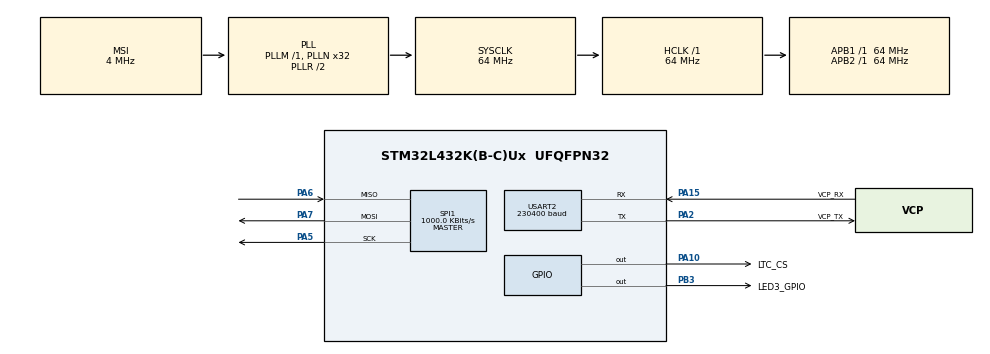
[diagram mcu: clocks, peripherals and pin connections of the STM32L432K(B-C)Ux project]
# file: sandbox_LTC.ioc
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Dma.Request0=USART2_RX
Dma.Request1=USART2_TX
Dma.USART2_RX.0.Direction=DMA_PERIPH_TO_MEMORY
Dma.USART2_RX.0.Instance=DMA1_Channel6
Dma.USART2_RX.0.MemDataAlignment=DMA_MDATAALIGN_BYTE
Dma.USART2_RX.0.MemInc=DMA_MINC_ENABLE
Dma.USART2_RX.0.Mode=DMA_CIRCULAR
Dma.USART2_RX.0.PeriphDataAlignment=DMA_PDATAALIGN_BYTE
Dma.USART2_RX.0.PeriphInc=DMA_PINC_DISABLE
Dma.USART2_RX.0.Priority=DMA_PRIORITY_VERY_HIGH
Dma.USART2_TX.1.Direction=DMA_MEMORY_TO_PERIPH
Dma.USART2_TX.1.Instance=DMA1_Channel7
Dma.USART2_TX.1.MemDataAlignment=DMA_MDATAALIGN_BYTE
Dma.USART2_TX.1.MemInc=DMA_MINC_ENABLE
Dma.USART2_TX.1.Mode=DMA_NORMAL
Dma.USART2_TX.1.PeriphDataAlignment=DMA_PDATAALIGN_BYTE
Dma.USART2_TX.1.PeriphInc=DMA_PINC_DISABLE
Dma.USART2_TX.1.Priority=DMA_PRIORITY_HIGH
Mcu.Family=STM32L4
Mcu.Name=STM32L432K(B-C)Ux
Mcu.Package=UFQFPN32
NVIC.DMA1_Channel6_IRQn=true\:0\:0\:false\:false\:true
NVIC.DMA1_Channel7_IRQn=true\:0\:0\:false\:false\:true
NVIC.PriorityGroup=NVIC_PRIORITYGROUP_4
NVIC.TIM6_DAC_IRQn=true\:0\:0\:false\:false\:true
NVIC.TimeBase=TIM6_DAC_IRQn
NVIC.TimeBaseIP=TIM6
NVIC.USART2_IRQn=true\:0\:0\:false\:false\:true
PA10.GPIO_Label=LTC_CS
PA10.Signal=GPIO_Output
PA13\ (JTMS-SWDIO).Mode=Serial_Wire
PA13\ (JTMS-SWDIO).Signal=SYS_JTMS-SWDIO
PA14\ (JTCK-SWCLK).Mode=Serial_Wire
PA14\ (JTCK-SWCLK).Signal=SYS_JTCK-SWCLK
PA15\ (JTDI).GPIO_Label=VCP_RX
PA15\ (JTDI).Mode=Asynchronous
PA15\ (JTDI).Signal=USART2_RX
PA2.GPIO_Label=VCP_TX
PA2.Mode=Asynchronous
PA2.Signal=USART2_TX
PA5.Mode=Full_Duplex_Master
PA5.Signal=SPI1_SCK
PA6.Mode=Full_Duplex_Master
PA6.Signal=SPI1_MISO
PA7.Mode=Full_Duplex_Master
PA7.Signal=SPI1_MOSI
PB3\ (JTDO-TRACESWO).GPIO_Label=LED3_GPIO
PB3\ (JTDO-TRACESWO).Signal=GPIO_Output
ProjectManager.HeapSize=0x200
ProjectManager.StackSize=0x400
ProjectManager.TargetToolchain=SW4STM32
RCC.AHBFreq_Value=64000000
RCC.APB1Freq_Value=64000000
RCC.APB1TimFreq_Value=64000000
RCC.APB2Freq_Value=64000000
RCC.APB2TimFreq_Value=64000000
RCC.CortexFreq_Value=64000000
RCC.HCLKFreq_Value=64000000
RCC.HSE_VALUE=8000000
RCC.HSI16_VALUE=16000000
RCC.HSI48_VALUE=48000000
RCC.HSI_VALUE=16000000
RCC.LSE_VALUE=32768
RCC.MSI_VALUE=4000000
RCC.PLLMUL=RCC_PLLMUL_4
RCC.PLLN=32
RCC.PREFETCH_ENABLE=1
RCC.SYSCLKFreq_VALUE=64000000
RCC.SYSCLKSource=RCC_SYSCLKSOURCE_PLLCLK
RCC.VCOOutputFreq_Value=128000000
SPI1.BaudRatePrescaler=SPI_BAUDRATEPRESCALER_64
SPI1.CLKPhase=SPI_PHASE_2EDGE
SPI1.CLKPolarity=SPI_POLARITY_HIGH
SPI1.CRCCalculation=SPI_CRCCALCULATION_DISABLE
SPI1.CalculateBaudRate=1000.0 KBits/s
SPI1.DataSize=SPI_DATASIZE_8BIT
SPI1.Mode=SPI_MODE_MASTER
USART2.BaudRate=230400
USART2.WordLength=UART_WORDLENGTH_8B
VP_SYS_VS_tim6.Mode=TIM6
board=NUCLEO-L432KC

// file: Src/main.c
/**
  ******************************************************************************
  * File Name          : main.c
  * Description        : Main program body
  ******************************************************************************
  *
  * COPYRIGHT(c) 2017 STMicroelectronics
  *
  * Redistribution and use in source and binary forms, with or without modification,
  * are permitted provided that the following conditions are met:
  *   1. Redistributions of source code must retain the above copyright notice,
  *      this list of conditions and the following disclaimer.
  *   2. Redistributions in binary form must reproduce the above copyright notice,
  *      this list of conditions and the following disclaimer in the documentation
  *      and/or other materials provided with the distribution.
  *   3. Neither the name of STMicroelectronics nor the names of its contributors
  *      may be used to endorse or promote products derived from this software
  *      without specific prior written permission.
  *
  * THIS SOFTWARE IS PROVIDED BY THE COPYRIGHT HOLDERS AND CONTRIBUTORS "AS IS"
  * AND ANY EXPRESS OR IMPLIED WARRANTIES, INCLUDING, BUT NOT LIMITED TO, THE
  * IMPLIED WARRANTIES OF MERCHANTABILITY AND FITNESS FOR A PARTICULAR PURPOSE ARE
  * DISCLAIMED. IN NO EVENT SHALL THE COPYRIGHT HOLDER OR CONTRIBUTORS BE LIABLE
  * FOR ANY DIRECT, INDIRECT, INCIDENTAL, SPECIAL, EXEMPLARY, OR CONSEQUENTIAL
  * DAMAGES (INCLUDING, BUT NOT LIMITED TO, PROCUREMENT OF SUBSTITUTE GOODS OR
  * SERVICES; LOSS OF USE, DATA, OR PROFITS; OR BUSINESS INTERRUPTION) HOWEVER
  * CAUSED AND ON ANY THEORY OF LIABILITY, WHETHER IN CONTRACT, STRICT LIABILITY,
  * OR TORT (INCLUDING NEGLIGENCE OR OTHERWISE) ARISING IN ANY WAY OUT OF THE USE
  * OF THIS SOFTWARE, EVEN IF ADVISED OF THE POSSIBILITY OF SUCH DAMAGE.
  *
  ******************************************************************************
  */
#include "main.h"
#include "stm32l4xx_hal.h"

/* USER CODE BEGIN Includes */
// NEW MAIN FILE!
#include "LTC6804.h"
/* USER CODE END Includes */

SPI_HandleTypeDef hspi1;

UART_HandleTypeDef huart2;
DMA_HandleTypeDef hdma_usart2_rx;
DMA_HandleTypeDef hdma_usart2_tx;

/* USER CODE BEGIN PV */
/* Private variables ---------------------------------------------------------*/

/* USER CODE END PV */

void SystemClock_Config(void);
void Error_Handler(void);
static void MX_GPIO_Init(void);
static void MX_DMA_Init(void);
static void MX_SPI1_Init(void);
static void MX_USART2_UART_Init(void);

/* USER CODE BEGIN PFP */
/* Private function prototypes -----------------------------------------------*/

/* USER CODE END PFP */

int main(void)
{

  /* MCU Configuration----------------------------------------------------------*/

  /* Reset of all peripherals, Initializes the Flash interface and the Systick. */
  HAL_Init();

  /* Configure the system clock */
  SystemClock_Config();

  /* Initialize all configured peripherals */
  MX_GPIO_Init();
  MX_DMA_Init();
  MX_SPI1_Init();
  MX_USART2_UART_Init();

  /* USER CODE BEGIN 2 */
  testfun();
  //uint8_t setup_msg1[] = "setup complete";
  //Serial2_writeBuf(setup_msg1);

  /* USER CODE END 2 */

  /* Infinite loop */
  while (1)
  {

  }

}

/** System Clock Configuration
*/
void SystemClock_Config(void)
{

  RCC_OscInitTypeDef RCC_OscInitStruct;
  RCC_ClkInitTypeDef RCC_ClkInitStruct;
  RCC_PeriphCLKInitTypeDef PeriphClkInit;

    /**Initializes the CPU, AHB and APB busses clocks
    */
  RCC_OscInitStruct.OscillatorType = RCC_OSCILLATORTYPE_MSI;
  RCC_OscInitStruct.MSIState = RCC_MSI_ON;
  RCC_OscInitStruct.MSICalibrationValue = 0;
  RCC_OscInitStruct.MSIClockRange = RCC_MSIRANGE_6;
  RCC_OscInitStruct.PLL.PLLState = RCC_PLL_ON;
  RCC_OscInitStruct.PLL.PLLSource = RCC_PLLSOURCE_MSI;
  RCC_OscInitStruct.PLL.PLLM = 1;
  RCC_OscInitStruct.PLL.PLLN = 32;
  RCC_OscInitStruct.PLL.PLLP = RCC_PLLP_DIV7;
  RCC_OscInitStruct.PLL.PLLQ = RCC_PLLQ_DIV2;
  RCC_OscInitStruct.PLL.PLLR = RCC_PLLR_DIV2;
  if (HAL_RCC_OscConfig(&RCC_OscInitStruct) != HAL_OK)
  {
    Error_Handler();
  }

    /**Initializes the CPU, AHB and APB busses clocks
    */
  RCC_ClkInitStruct.ClockType = RCC_CLOCKTYPE_HCLK|RCC_CLOCKTYPE_SYSCLK
                              |RCC_CLOCKTYPE_PCLK1|RCC_CLOCKTYPE_PCLK2;
  RCC_ClkInitStruct.SYSCLKSource = RCC_SYSCLKSOURCE_PLLCLK;
  RCC_ClkInitStruct.AHBCLKDivider = RCC_SYSCLK_DIV1;
  RCC_ClkInitStruct.APB1CLKDivider = RCC_HCLK_DIV1;
  RCC_ClkInitStruct.APB2CLKDivider = RCC_HCLK_DIV1;

  if (HAL_RCC_ClockConfig(&RCC_ClkInitStruct, FLASH_LATENCY_3) != HAL_OK)
  {
    Error_Handler();
  }

  PeriphClkInit.PeriphClockSelection = RCC_PERIPHCLK_USART2;
  PeriphClkInit.Usart2ClockSelection = RCC_USART2CLKSOURCE_PCLK1;
  if (HAL_RCCEx_PeriphCLKConfig(&PeriphClkInit) != HAL_OK)
  {
    Error_Handler();
  }

    /**Configure the main internal regulator output voltage
    */
  if (HAL_PWREx_ControlVoltageScaling(PWR_REGULATOR_VOLTAGE_SCALE1) != HAL_OK)
  {
    Error_Handler();
  }

    /**Configure the Systick interrupt time
    */
  HAL_SYSTICK_Config(HAL_RCC_GetHCLKFreq()/1000);

    /**Configure the Systick
    */
  HAL_SYSTICK_CLKSourceConfig(SYSTICK_CLKSOURCE_HCLK);

  /* SysTick_IRQn interrupt configuration */
  HAL_NVIC_SetPriority(SysTick_IRQn, 0, 0);
}

/* SPI1 init function */
static void MX_SPI1_Init(void)
{

  hspi1.Instance = SPI1;
  hspi1.Init.Mode = SPI_MODE_MASTER;
  hspi1.Init.Direction = SPI_DIRECTION_2LINES;
  hspi1.Init.DataSize = SPI_DATASIZE_8BIT;
  hspi1.Init.CLKPolarity = SPI_POLARITY_HIGH;
  hspi1.Init.CLKPhase = SPI_PHASE_2EDGE;
  hspi1.Init.NSS = SPI_NSS_SOFT;
  hspi1.Init.BaudRatePrescaler = SPI_BAUDRATEPRESCALER_64;
  hspi1.Init.FirstBit = SPI_FIRSTBIT_MSB;
  hspi1.Init.TIMode = SPI_TIMODE_DISABLE;
  hspi1.Init.CRCCalculation = SPI_CRCCALCULATION_DISABLE;
  hspi1.Init.CRCPolynomial = 7;
  hspi1.Init.CRCLength = SPI_CRC_LENGTH_DATASIZE;
  hspi1.Init.NSSPMode = SPI_NSS_PULSE_DISABLE;
  if (HAL_SPI_Init(&hspi1) != HAL_OK)
  {
    Error_Handler();
  }

}

/* USART2 init function */
static void MX_USART2_UART_Init(void)
{

  huart2.Instance = USART2;
  huart2.Init.BaudRate = 230400;
  huart2.Init.WordLength = UART_WORDLENGTH_8B;
  huart2.Init.StopBits = UART_STOPBITS_1;
  huart2.Init.Parity = UART_PARITY_NONE;
  huart2.Init.Mode = UART_MODE_TX_RX;
  huart2.Init.HwFlowCtl = UART_HWCONTROL_NONE;
  huart2.Init.OverSampling = UART_OVERSAMPLING_16;
  huart2.Init.OneBitSampling = UART_ONE_BIT_SAMPLE_DISABLE;
  huart2.AdvancedInit.AdvFeatureInit = UART_ADVFEATURE_NO_INIT;
  if (HAL_UART_Init(&huart2) != HAL_OK)
  {
    Error_Handler();
  }

}

static void MX_DMA_Init(void)
{
  /* DMA controller clock enable */
  LL_AHB1_GRP1_EnableClock(LL_AHB1_GRP1_PERIPH_DMA1);

  /* DMA interrupt init */
  /* DMA1_Channel6_IRQn interrupt configuration */
  HAL_NVIC_SetPriority(DMA1_Channel6_IRQn, 0, 0);
  HAL_NVIC_EnableIRQ(DMA1_Channel6_IRQn);
  /* DMA1_Channel7_IRQn interrupt configuration */
  HAL_NVIC_SetPriority(DMA1_Channel7_IRQn, 0, 0);
  HAL_NVIC_EnableIRQ(DMA1_Channel7_IRQn);

}

/** Configure pins as
        * Analog
        * Input
        * Output
        * EVENT_OUT
        * EXTI
*/
static void MX_GPIO_Init(void)
{

  GPIO_InitTypeDef GPIO_InitStruct;

  /* GPIO Ports Clock Enable */
  __HAL_RCC_GPIOA_CLK_ENABLE();
  __HAL_RCC_GPIOB_CLK_ENABLE();

  /*Configure GPIO pin Output Level */
  HAL_GPIO_WritePin(LTC_CS_GPIO_Port, LTC_CS_Pin, GPIO_PIN_RESET);

  /*Configure GPIO pin Output Level */
  HAL_GPIO_WritePin(LED3_GPIO_GPIO_Port, LED3_GPIO_Pin, GPIO_PIN_RESET);

  /*Configure GPIO pin : LTC_CS_Pin */
  GPIO_InitStruct.Pin = LTC_CS_Pin;
  GPIO_InitStruct.Mode = GPIO_MODE_OUTPUT_PP;
  GPIO_InitStruct.Pull = GPIO_NOPULL;
  GPIO_InitStruct.Speed = GPIO_SPEED_FREQ_LOW;
  HAL_GPIO_Init(LTC_CS_GPIO_Port, &GPIO_InitStruct);

  /*Configure GPIO pin : LED3_GPIO_Pin */
  GPIO_InitStruct.Pin = LED3_GPIO_Pin;
  GPIO_InitStruct.Mode = GPIO_MODE_OUTPUT_PP;
  GPIO_InitStruct.Pull = GPIO_NOPULL;
  GPIO_InitStruct.Speed = GPIO_SPEED_FREQ_LOW;
  HAL_GPIO_Init(LED3_GPIO_GPIO_Port, &GPIO_InitStruct);

}

void HAL_TIM_PeriodElapsedCallback(TIM_HandleTypeDef *htim)
{
  if (htim->Instance == TIM6) {
    HAL_IncTick();
  }
}

void Error_Handler(void)
{
  /* USER CODE BEGIN Error_Handler */
	HAL_GPIO_WritePin (LED3_GPIO_GPIO_Port, LED3_GPIO_Pin, GPIO_PIN_SET);
  /* User can add his own implementation to report the HAL error return state */
  while(1)
  {
	  uint8_t error_msg[] = "error exist!";
	  Serial2_writeBuf(error_msg);

  }
  /* USER CODE END Error_Handler */
}

/************************ (C) COPYRIGHT STMicroelectronics *****END OF FILE****/
